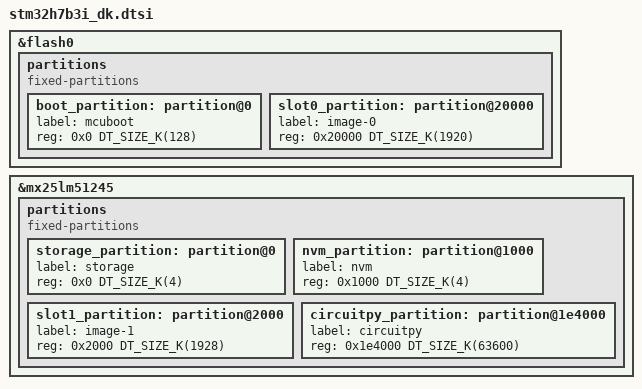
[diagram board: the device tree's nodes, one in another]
&flash0 {
	partitions {
		compatible = "fixed-partitions";
		#address-cells = <1>;
		#size-cells = <1>;

		boot_partition: partition@0 {
			label = "mcuboot";
			reg = <0x0 DT_SIZE_K(128)>;
		};

		slot0_partition: partition@20000 {
			label = "image-0";
			reg = <0x20000 DT_SIZE_K(1920)>;
		};
	};
};

&mx25lm51245 {
	partitions {
		compatible = "fixed-partitions";
		#address-cells = <1>;
		#size-cells = <1>;

		storage_partition: partition@0 {
			label = "storage";
			reg = <0x0 DT_SIZE_K(4)>;
		};

		nvm_partition: partition@1000 {
			label = "nvm";
			reg = <0x1000 DT_SIZE_K(4)>;
		};

		slot1_partition: partition@2000 {
			label = "image-1";
			reg = <0x2000 DT_SIZE_K(1928)>;
		};

		circuitpy_partition: partition@1e4000 {
			label = "circuitpy";
			reg = <0x1e4000 DT_SIZE_K(63600)>;
		};
	};
};
